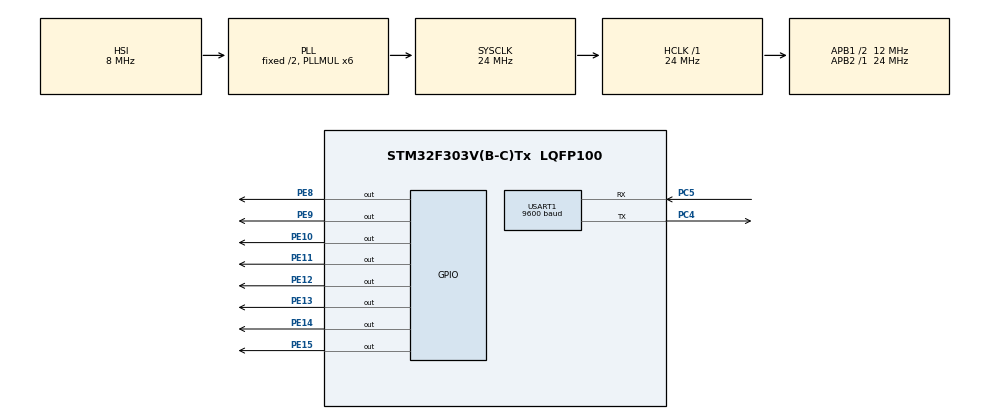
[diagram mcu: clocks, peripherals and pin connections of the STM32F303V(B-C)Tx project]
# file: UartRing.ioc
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Mcu.Family=STM32F3
Mcu.Name=STM32F303V(B-C)Tx
Mcu.Package=LQFP100
NVIC.PriorityGroup=NVIC_PRIORITYGROUP_0
NVIC.USART1_IRQn=true\:0\:0\:false\:false\:true\:true\:true\:true
PC4.Mode=Asynchronous
PC4.Signal=USART1_TX
PC5.Mode=Asynchronous
PC5.Signal=USART1_RX
PE10.Signal=GPIO_Output
PE11.Signal=GPIO_Output
PE12.Signal=GPIO_Output
PE13.Signal=GPIO_Output
PE14.Signal=GPIO_Output
PE15.Signal=GPIO_Output
PE8.Signal=GPIO_Output
PE9.Signal=GPIO_Output
ProjectManager.HeapSize=0x200
ProjectManager.StackSize=0x400
ProjectManager.TargetToolchain=STM32CubeIDE
RCC.AHBFreq_Value=24000000
RCC.APB1CLKDivider=RCC_HCLK_DIV2
RCC.APB1Freq_Value=12000000
RCC.APB1TimFreq_Value=24000000
RCC.APB2Freq_Value=24000000
RCC.APB2TimFreq_Value=24000000
RCC.CortexFreq_Value=24000000
RCC.HCLKFreq_Value=24000000
RCC.HSE_VALUE=8000000
RCC.HSI_VALUE=8000000
RCC.LSE_VALUE=32768
RCC.PLLMUL=RCC_PLL_MUL6
RCC.SYSCLKFreq_VALUE=24000000
RCC.SYSCLKSourceVirtual=RCC_SYSCLKSOURCE_PLLCLK
RCC.USBFreq_Value=24000000
USART1.BaudRate=9600
USART1.VirtualMode-Asynchronous=VM_ASYNC
board=STM32F3DISCOVERY

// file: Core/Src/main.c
/* USER CODE BEGIN Header */
/**
  ******************************************************************************
  * @file           : main.c
  * @brief          : Main program body
  ******************************************************************************
  * @attention
  *
  * Copyright (c) 2023 STMicroelectronics.
  * All rights reserved.
  *
  * This software is licensed under terms that can be found in the LICENSE file
  * in the root directory of this software component.
  * If no LICENSE file comes with this software, it is provided AS-IS.
  *
  ******************************************************************************
  */
/* USER CODE END Header */
#include "main.h"
#include "string.h"

 UART_HandleTypeDef huart1;

void SystemClock_Config(void);
static void MX_GPIO_Init(void);
static void MX_USART1_UART_Init(void);

/* USER CODE BEGIN 0 */

unsigned char RXdata[10];
unsigned char RXpin[10]="omkarsawan";

/* USER CODE END 0 */

int main(void)
{

  /* MCU Configuration--------------------------------------------------------*/

  /* Reset of all peripherals, Initializes the Flash interface and the Systick. */
  HAL_Init();

  /* Configure the system clock */
  SystemClock_Config();

  /* Initialize all configured peripherals */
  MX_GPIO_Init();
  MX_USART1_UART_Init();
//  HAL_UART_Receive(&huart1, RXdata, sizeof(RXdata), 20);
//
//  static uint8_t ledpin = 8;
//  HAL_GPIO_TogglePin(GPIOE, 1<<ledpin);
//  ledpin++;
//  if(ledpin>16){
//	  ledpin=8;
//	  HAL_GPIO_TogglePin(GPIOE, 1<<ledpin);
//	  ledpin++;
//  }

  /* Infinite loop */
  while (1)
  {
	  HAL_UART_Receive(&huart1, RXdata, sizeof(RXdata), 500);

	  for(int i=0;i<10;i++){
		  HAL_Delay(20);
		  if(RXdata[i]==RXpin[i]){
			  static uint8_t ledpin = 8;
			  HAL_GPIO_TogglePin(GPIOE, 1<<ledpin);
			  ledpin++;
			  if(ledpin>16){
				  ledpin=8;
				  HAL_GPIO_TogglePin(GPIOE, 1<<ledpin);
				  ledpin++;
			  }
		  }
	  }

  }
}

void SystemClock_Config(void)
{
  RCC_OscInitTypeDef RCC_OscInitStruct = {0};
  RCC_ClkInitTypeDef RCC_ClkInitStruct = {0};
  RCC_PeriphCLKInitTypeDef PeriphClkInit = {0};

  /** Initializes the RCC Oscillators according to the specified parameters
  * in the RCC_OscInitTypeDef structure.
  */
  RCC_OscInitStruct.OscillatorType = RCC_OSCILLATORTYPE_HSI;
  RCC_OscInitStruct.HSIState = RCC_HSI_ON;
  RCC_OscInitStruct.HSICalibrationValue = RCC_HSICALIBRATION_DEFAULT;
  RCC_OscInitStruct.PLL.PLLState = RCC_PLL_ON;
  RCC_OscInitStruct.PLL.PLLSource = RCC_PLLSOURCE_HSI;
  RCC_OscInitStruct.PLL.PLLMUL = RCC_PLL_MUL6;
  if (HAL_RCC_OscConfig(&RCC_OscInitStruct) != HAL_OK)
  {
    Error_Handler();
  }

  /** Initializes the CPU, AHB and APB buses clocks
  */
  RCC_ClkInitStruct.ClockType = RCC_CLOCKTYPE_HCLK|RCC_CLOCKTYPE_SYSCLK
                              |RCC_CLOCKTYPE_PCLK1|RCC_CLOCKTYPE_PCLK2;
  RCC_ClkInitStruct.SYSCLKSource = RCC_SYSCLKSOURCE_PLLCLK;
  RCC_ClkInitStruct.AHBCLKDivider = RCC_SYSCLK_DIV1;
  RCC_ClkInitStruct.APB1CLKDivider = RCC_HCLK_DIV2;
  RCC_ClkInitStruct.APB2CLKDivider = RCC_HCLK_DIV1;

  if (HAL_RCC_ClockConfig(&RCC_ClkInitStruct, FLASH_LATENCY_0) != HAL_OK)
  {
    Error_Handler();
  }
  PeriphClkInit.PeriphClockSelection = RCC_PERIPHCLK_USART1;
  PeriphClkInit.Usart1ClockSelection = RCC_USART1CLKSOURCE_PCLK2;
  if (HAL_RCCEx_PeriphCLKConfig(&PeriphClkInit) != HAL_OK)
  {
    Error_Handler();
  }
}

static void MX_USART1_UART_Init(void)
{

  huart1.Instance = USART1;
  huart1.Init.BaudRate = 9600;
  huart1.Init.WordLength = UART_WORDLENGTH_8B;
  huart1.Init.StopBits = UART_STOPBITS_1;
  huart1.Init.Parity = UART_PARITY_NONE;
  huart1.Init.Mode = UART_MODE_TX_RX;
  huart1.Init.HwFlowCtl = UART_HWCONTROL_NONE;
  huart1.Init.OverSampling = UART_OVERSAMPLING_16;
  huart1.Init.OneBitSampling = UART_ONE_BIT_SAMPLE_DISABLE;
  huart1.AdvancedInit.AdvFeatureInit = UART_ADVFEATURE_NO_INIT;
  if (HAL_UART_Init(&huart1) != HAL_OK)
  {
    Error_Handler();
  }

}

static void MX_GPIO_Init(void)
{
  GPIO_InitTypeDef GPIO_InitStruct = {0};

  /* GPIO Ports Clock Enable */
  __HAL_RCC_GPIOC_CLK_ENABLE();
  __HAL_RCC_GPIOE_CLK_ENABLE();

  /*Configure GPIO pin Output Level */
  HAL_GPIO_WritePin(GPIOE, GPIO_PIN_8|GPIO_PIN_9|GPIO_PIN_10|GPIO_PIN_11
                          |GPIO_PIN_12|GPIO_PIN_13|GPIO_PIN_14|GPIO_PIN_15, GPIO_PIN_RESET);

  /*Configure GPIO pins : PE8 PE9 PE10 PE11
                           PE12 PE13 PE14 PE15 */
  GPIO_InitStruct.Pin = GPIO_PIN_8|GPIO_PIN_9|GPIO_PIN_10|GPIO_PIN_11
                          |GPIO_PIN_12|GPIO_PIN_13|GPIO_PIN_14|GPIO_PIN_15;
  GPIO_InitStruct.Mode = GPIO_MODE_OUTPUT_PP;
  GPIO_InitStruct.Pull = GPIO_NOPULL;
  GPIO_InitStruct.Speed = GPIO_SPEED_FREQ_LOW;
  HAL_GPIO_Init(GPIOE, &GPIO_InitStruct);

}

void Error_Handler(void)
{
  __disable_irq();
  while (1)
  {
  }
}
